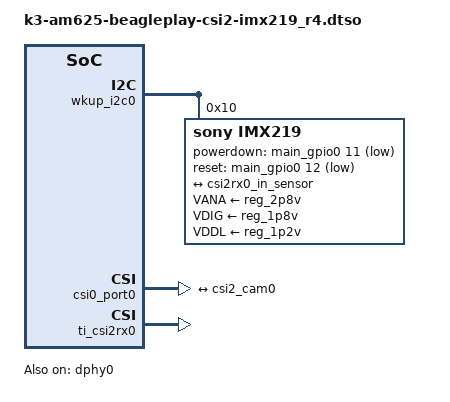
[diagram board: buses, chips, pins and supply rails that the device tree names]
// SPDX-License-Identifier: GPL-2.0-only OR MIT
/*
 * Raspberry Pi Camera V2 (Sony IMX219)
 * for BeaglePlay
 */

/dts-v1/;
/plugin/;

#include <dt-bindings/gpio/gpio.h>

/ {
	clk_imx219_fixed: imx219-xclk {
		compatible = "fixed-clock";
		#clock-cells = <0>;
		clock-frequency = <24000000>;
	};
/*
	reg_2p8v: regulator-2p8v {
		compatible = "regulator-fixed";
		regulator-name = "2P8V";
		regulator-min-microvolt = <2800000>;
		regulator-max-microvolt = <2800000>;
		vin-supply = <&vdd_3v3>;
		regulator-always-on;
	};

	reg_1p8v: regulator-1p8v {
		compatible = "regulator-fixed";
		regulator-name = "1P8V";
		regulator-min-microvolt = <1800000>;
		regulator-max-microvolt = <1800000>;
		vin-supply = <&vdd_3v3>;
		regulator-always-on;
	};

	reg_1p2v: regulator-1p2v {
		compatible = "regulator-fixed";
		regulator-name = "1P2V";
		regulator-min-microvolt = <1200000>;
		regulator-max-microvolt = <1200000>;
		vin-supply = <&vdd_3v3>;
		regulator-always-on;
	};
*/
};

// &main_gpio0 {
// 	p11-hog {
// 		/* P11 - CSI2_CAMERA_GPIO1 */
// 		gpio-hog;
// 		gpios = <11 GPIO_ACTIVE_HIGH>;
// 		output-high;
// 		line-name = "CSI2_CAMERA_GPIO1";
// 	};
// };

&wkup_i2c0 {
	#address-cells = <1>;
	#size-cells = <0>;
	status = "okay";

	imx219: camera@10 {
		compatible = "sony,imx219";
		reg = <0x10>;

		clocks = <&clk_imx219_fixed>;
		clock-names = "xclk";

		VANA-supply = <&reg_2p8v>;
		VDIG-supply = <&reg_1p8v>;
		VDDL-supply = <&reg_1p2v>;

		powerdown-gpios = <&main_gpio0 11 GPIO_ACTIVE_LOW>;
		reset-gpios = <&main_gpio0 12 GPIO_ACTIVE_LOW>;

		port {
			csi2_cam0: endpoint {
				remote-endpoint = <&csi2rx0_in_sensor>;
				link-frequencies = /bits/ 64 <456000000>;
				clock-lanes = <0>;
				data-lanes = <1 2>;
			};
		};
	};
};

&csi0_port0 {
	reg = <0>;
	status = "okay";

	csi2rx0_in_sensor: endpoint {
		remote-endpoint = <&csi2_cam0>;
		bus-type = <4>;
		clock-lanes = <0>;
		data-lanes = <1 2>;
	};
};

&dphy0 {
	status = "okay";
};

&ti_csi2rx0 {
	status = "okay";
};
